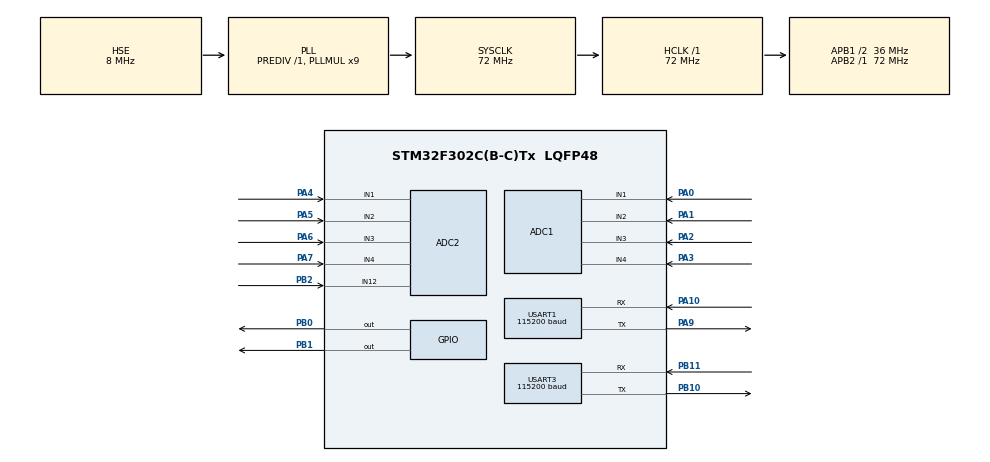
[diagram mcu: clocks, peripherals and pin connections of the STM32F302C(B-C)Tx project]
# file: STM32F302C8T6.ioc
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ADC1.Channel-12\#ChannelRegularConversion=ADC_CHANNEL_1
ADC1.Channel-13\#ChannelRegularConversion=ADC_CHANNEL_2
ADC1.Channel-14\#ChannelRegularConversion=ADC_CHANNEL_3
ADC1.Channel-15\#ChannelRegularConversion=ADC_CHANNEL_4
ADC1.ClockPrescaler=ADC_CLOCK_SYNC_PCLK_DIV4
ADC1.ContinuousConvMode=ENABLE
ADC1.DMAContinuousRequests=ENABLE
ADC1.NbrOfConversion=4
ADC1.NbrOfConversionFlag=1
ADC1.Offset-12\#ChannelRegularConversion=0
ADC1.Offset-13\#ChannelRegularConversion=0
ADC1.Offset-14\#ChannelRegularConversion=0
ADC1.Offset-15\#ChannelRegularConversion=0
ADC1.OffsetNumber-12\#ChannelRegularConversion=ADC_OFFSET_NONE
ADC1.OffsetNumber-13\#ChannelRegularConversion=ADC_OFFSET_NONE
ADC1.OffsetNumber-14\#ChannelRegularConversion=ADC_OFFSET_NONE
ADC1.OffsetNumber-15\#ChannelRegularConversion=ADC_OFFSET_NONE
ADC1.Rank-12\#ChannelRegularConversion=1
ADC1.Rank-13\#ChannelRegularConversion=2
ADC1.Rank-14\#ChannelRegularConversion=3
ADC1.Rank-15\#ChannelRegularConversion=4
ADC1.SamplingTime-12\#ChannelRegularConversion=ADC_SAMPLETIME_181CYCLES_5
ADC1.SamplingTime-13\#ChannelRegularConversion=ADC_SAMPLETIME_181CYCLES_5
ADC1.SamplingTime-14\#ChannelRegularConversion=ADC_SAMPLETIME_181CYCLES_5
ADC1.SamplingTime-15\#ChannelRegularConversion=ADC_SAMPLETIME_181CYCLES_5
ADC1.master=1
ADC2.Channel-13\#ChannelRegularConversion=ADC_CHANNEL_1
ADC2.Channel-14\#ChannelRegularConversion=ADC_CHANNEL_2
ADC2.Channel-15\#ChannelRegularConversion=ADC_CHANNEL_3
ADC2.Channel-16\#ChannelRegularConversion=ADC_CHANNEL_4
ADC2.Channel-17\#ChannelRegularConversion=ADC_CHANNEL_12
ADC2.ClockPrescaler=ADC_CLOCK_SYNC_PCLK_DIV4
ADC2.ContinuousConvMode=ENABLE
ADC2.DMAContinuousRequests=ENABLE
ADC2.NbrOfConversion=5
ADC2.NbrOfConversionFlag=1
ADC2.Offset-13\#ChannelRegularConversion=0
ADC2.Offset-14\#ChannelRegularConversion=0
ADC2.Offset-15\#ChannelRegularConversion=0
ADC2.Offset-16\#ChannelRegularConversion=0
ADC2.Offset-17\#ChannelRegularConversion=0
ADC2.OffsetNumber-13\#ChannelRegularConversion=ADC_OFFSET_NONE
ADC2.OffsetNumber-14\#ChannelRegularConversion=ADC_OFFSET_NONE
ADC2.OffsetNumber-15\#ChannelRegularConversion=ADC_OFFSET_NONE
ADC2.OffsetNumber-16\#ChannelRegularConversion=ADC_OFFSET_NONE
ADC2.OffsetNumber-17\#ChannelRegularConversion=ADC_OFFSET_NONE
ADC2.Rank-13\#ChannelRegularConversion=1
ADC2.Rank-14\#ChannelRegularConversion=2
ADC2.Rank-15\#ChannelRegularConversion=3
ADC2.Rank-16\#ChannelRegularConversion=4
ADC2.Rank-17\#ChannelRegularConversion=5
ADC2.SamplingTime-13\#ChannelRegularConversion=ADC_SAMPLETIME_181CYCLES_5
ADC2.SamplingTime-14\#ChannelRegularConversion=ADC_SAMPLETIME_181CYCLES_5
ADC2.SamplingTime-15\#ChannelRegularConversion=ADC_SAMPLETIME_181CYCLES_5
ADC2.SamplingTime-16\#ChannelRegularConversion=ADC_SAMPLETIME_181CYCLES_5
ADC2.SamplingTime-17\#ChannelRegularConversion=ADC_SAMPLETIME_181CYCLES_5
Dma.ADC1.0.Direction=DMA_PERIPH_TO_MEMORY
Dma.ADC1.0.Instance=DMA1_Channel1
Dma.ADC1.0.MemDataAlignment=DMA_MDATAALIGN_WORD
Dma.ADC1.0.MemInc=DMA_MINC_ENABLE
Dma.ADC1.0.Mode=DMA_CIRCULAR
Dma.ADC1.0.PeriphDataAlignment=DMA_PDATAALIGN_WORD
Dma.ADC1.0.PeriphInc=DMA_PINC_DISABLE
Dma.ADC1.0.Priority=DMA_PRIORITY_LOW
Dma.ADC2.1.Direction=DMA_PERIPH_TO_MEMORY
Dma.ADC2.1.Instance=DMA2_Channel1
Dma.ADC2.1.MemDataAlignment=DMA_MDATAALIGN_WORD
Dma.ADC2.1.MemInc=DMA_MINC_ENABLE
Dma.ADC2.1.Mode=DMA_CIRCULAR
Dma.ADC2.1.PeriphDataAlignment=DMA_PDATAALIGN_WORD
Dma.ADC2.1.PeriphInc=DMA_PINC_DISABLE
Dma.ADC2.1.Priority=DMA_PRIORITY_LOW
Dma.Request0=ADC1
Dma.Request1=ADC2
Mcu.Family=STM32F3
Mcu.Name=STM32F302C(B-C)Tx
Mcu.Package=LQFP48
NVIC.DMA1_Channel1_IRQn=true\:0\:0\:false\:false\:true\:false\:true
NVIC.DMA2_Channel1_IRQn=true\:0\:0\:false\:false\:true\:false\:true
NVIC.PriorityGroup=NVIC_PRIORITYGROUP_4
NVIC.USART1_IRQn=true\:1\:0\:true\:false\:true\:true\:true
NVIC.USART3_IRQn=true\:3\:0\:true\:false\:true\:true\:true
PA0.Mode=IN1-Single-Ended
PA0.Signal=ADC1_IN1
PA1.Mode=IN2-Single-Ended
PA1.Signal=ADC1_IN2
PA10.Mode=Asynchronous
PA10.Signal=USART1_RX
PA2.Mode=IN3-Single-Ended
PA2.Signal=ADC1_IN3
PA3.Mode=IN4-Single-Ended
PA3.Signal=ADC1_IN4
PA4.Mode=IN1-Single-Ended
PA4.Signal=ADC2_IN1
PA5.Mode=IN2-Single-Ended
PA5.Signal=ADC2_IN2
PA6.Mode=IN3-Single-Ended
PA6.Signal=ADC2_IN3
PA7.Mode=IN4-Single-Ended
PA7.Signal=ADC2_IN4
PA9.Mode=Asynchronous
PA9.Signal=USART1_TX
PB0.Signal=GPIO_Output
PB1.Signal=GPIO_Output
PB10.Mode=Asynchronous
PB10.Signal=USART3_TX
PB11.Mode=Asynchronous
PB11.Signal=USART3_RX
PB2.Mode=IN12-Single-Ended
PB2.Signal=ADC2_IN12
PF0-OSC_IN.Mode=HSE-External-Oscillator
PF0-OSC_IN.Signal=RCC_OSC_IN
PF1-OSC_OUT.Mode=HSE-External-Oscillator
PF1-OSC_OUT.Signal=RCC_OSC_OUT
ProjectManager.HeapSize=0x200
ProjectManager.StackSize=0x400
ProjectManager.TargetToolchain=MDK-ARM V5
RCC.AHBFreq_Value=72000000
RCC.APB1CLKDivider=RCC_HCLK_DIV2
RCC.APB1Freq_Value=36000000
RCC.APB1TimFreq_Value=72000000
RCC.APB2Freq_Value=72000000
RCC.APB2TimFreq_Value=72000000
RCC.CortexFreq_Value=72000000
RCC.HCLKFreq_Value=72000000
RCC.HSE_VALUE=8000000
RCC.HSI_VALUE=8000000
RCC.LSE_VALUE=32768
RCC.PLLMUL=RCC_PLL_MUL9
RCC.PLLSourceVirtual=RCC_PLLSOURCE_HSE
RCC.SYSCLKFreq_VALUE=72000000
RCC.SYSCLKSourceVirtual=RCC_SYSCLKSOURCE_PLLCLK
RCC.USBFreq_Value=72000000
USART1.BaudRate=115200
USART1.VirtualMode-Asynchronous=VM_ASYNC
USART3.BaudRate=115200
USART3.VirtualMode-Asynchronous=VM_ASYNC
board=custom

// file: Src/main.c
/* USER CODE BEGIN Header */
/**
  ******************************************************************************
  * @file           : main.c
  * @brief          : Main program body
  ******************************************************************************
  * @attention
  *
  * <h2><center>&copy; Copyright (c) 2019 STMicroelectronics.
  * All rights reserved.</center></h2>
  *
  * This software component is licensed by ST under BSD 3-Clause license,
  * the "License"; You may not use this file except in compliance with the
  * License. You may obtain a copy of the License at:
  *                        opensource.org/licenses/BSD-3-Clause
  *
  ******************************************************************************
  */
	/*
	V2.0版本 2019.0809
	*/
/* USER CODE END Header */

#include "main.h"
#include "adc.h"
#include "dma.h"
#include "usart.h"
#include "gpio.h"

/* USER CODE BEGIN Includes */
//#include "bsp.h"
#include "joystick.h"
/* USER CODE END Includes */

void SystemClock_Config(void);

/* USER CODE BEGIN 0 */
uint8_t timeout = 0;
/* USER CODE END 0 */

int main(void)
{

  /* MCU Configuration--------------------------------------------------------*/

  /* Reset of all peripherals, Initializes the Flash interface and the Systick. */
  HAL_Init();

  /* Configure the system clock */
  SystemClock_Config();

  /* Initialize all configured peripherals */
  MX_GPIO_Init();
  MX_DMA_Init();
  MX_USART1_UART_Init();
  MX_USART3_UART_Init();
  MX_ADC1_Init();
  MX_ADC2_Init();
  /* USER CODE BEGIN 2 */
  ADC_DataLinkInit();
  USART_IT_Start();

  HAL_Delay(1000);//延时1秒等待adc初始化，否则
  /* USER CODE END 2 */

  /* Infinite loop */
  while (1)
  {

    /* USER CODE BEGIN 3 */
	 HandleAdcData();
	 //HAL_GPIO_TogglePin(GPIOB,GPIO_PIN_12);;
	 //HAL_Delay(100);
	 if(timeout!=0)		//串口中断出现延时后，手动使能
	 {
		HAL_UART_Receive_IT(&huart1,&Uart1RX_Data,1);
		HAL_UART_Receive_IT(&huart3,&Uart3RX_Data,1);
		timeout = 0;
	 }
	 HandleUsart1Screen();
	 HandleUsart3Pc();

  }
  /* USER CODE END 3 */
}

void SystemClock_Config(void)
{
  RCC_OscInitTypeDef RCC_OscInitStruct = {0};
  RCC_ClkInitTypeDef RCC_ClkInitStruct = {0};
  RCC_PeriphCLKInitTypeDef PeriphClkInit = {0};

  /** Initializes the CPU, AHB and APB busses clocks
  */
  RCC_OscInitStruct.OscillatorType = RCC_OSCILLATORTYPE_HSE;
  RCC_OscInitStruct.HSEState = RCC_HSE_ON;
  RCC_OscInitStruct.HSEPredivValue = RCC_HSE_PREDIV_DIV1;
  RCC_OscInitStruct.HSIState = RCC_HSI_ON;
  RCC_OscInitStruct.PLL.PLLState = RCC_PLL_ON;
  RCC_OscInitStruct.PLL.PLLSource = RCC_PLLSOURCE_HSE;
  RCC_OscInitStruct.PLL.PLLMUL = RCC_PLL_MUL9;
  if (HAL_RCC_OscConfig(&RCC_OscInitStruct) != HAL_OK)
  {
    Error_Handler();
  }
  /** Initializes the CPU, AHB and APB busses clocks
  */
  RCC_ClkInitStruct.ClockType = RCC_CLOCKTYPE_HCLK|RCC_CLOCKTYPE_SYSCLK
                              |RCC_CLOCKTYPE_PCLK1|RCC_CLOCKTYPE_PCLK2;
  RCC_ClkInitStruct.SYSCLKSource = RCC_SYSCLKSOURCE_PLLCLK;
  RCC_ClkInitStruct.AHBCLKDivider = RCC_SYSCLK_DIV1;
  RCC_ClkInitStruct.APB1CLKDivider = RCC_HCLK_DIV2;
  RCC_ClkInitStruct.APB2CLKDivider = RCC_HCLK_DIV1;

  if (HAL_RCC_ClockConfig(&RCC_ClkInitStruct, FLASH_LATENCY_2) != HAL_OK)
  {
    Error_Handler();
  }
  PeriphClkInit.PeriphClockSelection = RCC_PERIPHCLK_USART1|RCC_PERIPHCLK_USART3;
  PeriphClkInit.Usart1ClockSelection = RCC_USART1CLKSOURCE_PCLK2;
  PeriphClkInit.Usart3ClockSelection = RCC_USART3CLKSOURCE_PCLK1;
  if (HAL_RCCEx_PeriphCLKConfig(&PeriphClkInit) != HAL_OK)
  {
    Error_Handler();
  }
}

void Error_Handler(void)
{
}

/************************ (C) COPYRIGHT STMicroelectronics *****END OF FILE****/
